# FM33FH0XX register map
File version: 1.0
CPU: SC000 r1p0, little endian, no MPU, no FPU, 3 interrupt priority bits
Registers are 32-bit, read-write, reset 0x0 unless marked. A register's access mark holds for its fields unless they carry their own. Offsets are from the block's base; [hi:lo] are bit positions.

## BSTIM16 — BSTIM16 module information
Base 0x4001B400
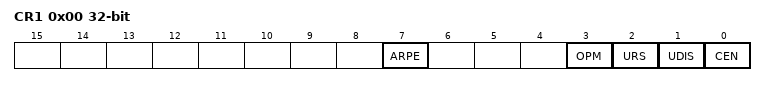
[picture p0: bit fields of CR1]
0x00 CR1
  [7] ARPE — ARPE field description
  [3] OPM — OPM field description
  [2] URS — URS field description
  [1] UDIS — UDIS field description
  [0] CEN — CEN field description
0x04 CR2
  [6:4] MMS — MMS field description
0x0C DIER
  [0] UIE — UIE field description
0x10 ISR
  [0] UIF — UIF field description
0x14 EGR
  [0] UG ro — UG field description
0x24 CNT
  [15:0] CNT ro — CNT field description
0x28 PSC
  [15:0] PSC — PSC field description
0x2C ARR
  [15:0] ARR — ARR field description

## CLM0 — CLM0 module information
Base 0x4001C000
Same registers: CLM1 0x4001C400, CLM2 0x4001C800
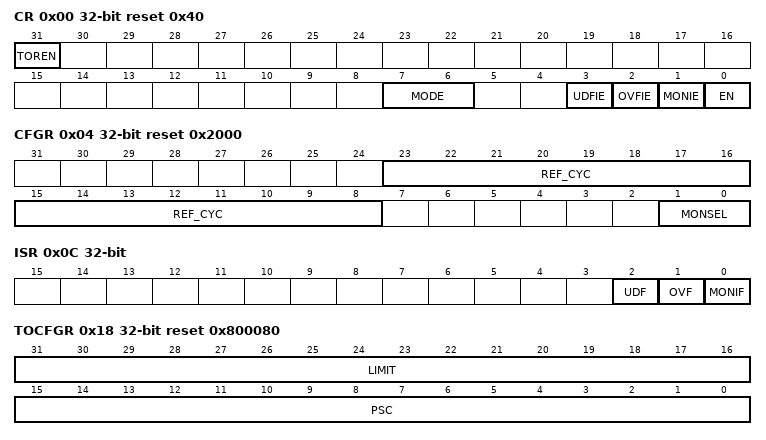
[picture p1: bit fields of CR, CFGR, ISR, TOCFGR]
0x00 CR reset 0x40
  [31] TOREN — TOREN field description
  [7:6] MODE — MODE field description
  [3] UDFIE — UDFIE field description
  [2] OVFIE — OVFIE field description
  [1] MONIE — MONIE field description
  [0] EN — EN field description
0x04 CFGR reset 0x2000
  [23:8] REF_CYC — REF_CYC field description
  [1:0] MONSEL — MONSEL field description
0x08 CNTR
  [23:0] CNT ro — CNT field description
0x0C ISR
  [2] UDF — UDF field description
  [1] OVF — OVF field description
  [0] MONIF — MONIF field description
0x10 CMPH reset 0xFF0000
  [23:0] CMPH — CMPH field description
0x14 CMPL reset 0xFF
  [23:0] CMPL — CMPL field description
0x18 TOCFGR reset 0x800080
  [31:16] LIMIT — LIMIT field description
  [15:0] PSC — PSC field description

## COMP — COMP module information
Base 0x40019C00
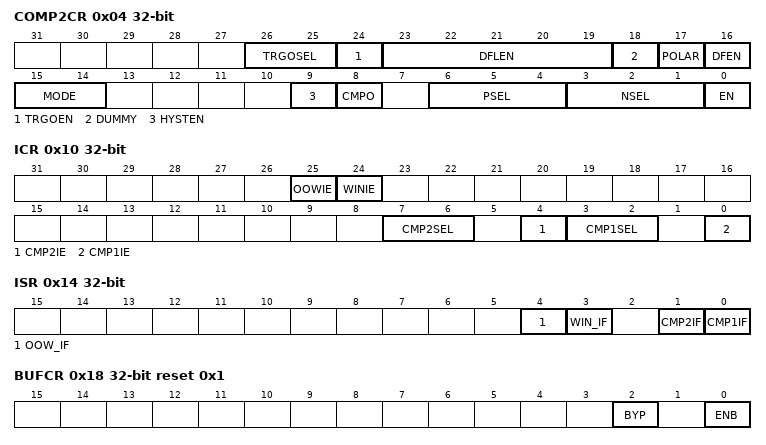
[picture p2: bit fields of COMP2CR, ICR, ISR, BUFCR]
0x04 COMP2CR
  [26:25] TRGOSEL — TRGOSEL field description
  [24] TRGOEN — TRGOEN field description
  [23:19] DFLEN — DFLEN field description
  [18] DUMMY — DUMMY field description
  [17] POLAR — POLAR field description
  [16] DFEN — DFEN field description
  [15:14] MODE — MODE field description
  [9] HYSTEN — HYSTEN field description
  [8] CMPO ro — CMPO field description
  [6:4] PSEL — PSEL field description
  [3:1] NSEL — NSEL field description
  [0] EN — EN field description
0x10 ICR
  [25] OOWIE — OOWIE field description
  [24] WINIE — WINIE field description
  [7:6] CMP2SEL — CMP2SEL field description
  [4] CMP2IE — CMP2IE field description
  [3:2] CMP1SEL — CMP1SEL field description
  [0] CMP1IE — CMP1IE field description
0x14 ISR
  [4] OOW_IF — OOW_IF field description
  [3] WIN_IF — WIN_IF field description
  [1] CMP2IF — CMP2IF field description
  [0] CMP1IF — CMP1IF field description
0x18 BUFCR reset 0x1
  [2] BYP — BYP field description
  [0] ENB — ENB field description

## CRC — CRC module information
Base 0x40018000
0x00 DR reset 0xFFFFFFFF
  [31:0] DR — DR field description
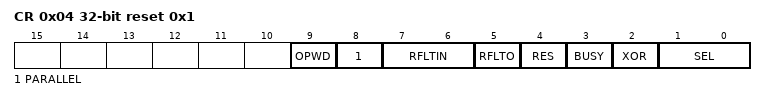
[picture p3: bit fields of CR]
0x04 CR reset 0x1
  [9] OPWD — OPWD field description
  [8] PARALLEL — PARALLEL field description
  [7:6] RFLTIN — RFLTIN field description
  [5] RFLTO — RFLTO field description
  [4] RES ro — RES field description
  [3] BUSY ro — BUSY field description
  [2] XOR — XOR field description
  [1:0] SEL — SEL field description
0x08 LFSR reset 0xFFFFFFFF
  [31:0] LFSR — LFSR field description
0x0C XOR
  [31:0] XOR — XOR field description
0x1C POLY reset 0x1021
  [31:0] POLY — POLY field description

## DAC — DAC module information
Base 0x40012C00
0x00 CR1
  [0] EN — EN field description
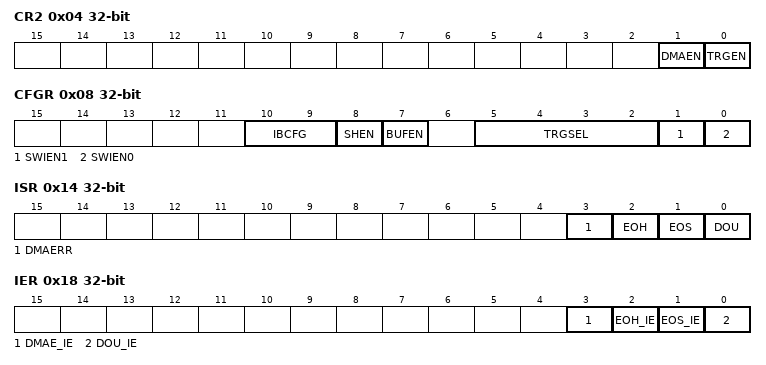
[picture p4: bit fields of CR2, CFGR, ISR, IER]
0x04 CR2
  [1] DMAEN — DMAEN field description
  [0] TRGEN — TRGEN field description
0x08 CFGR
  [10:9] IBCFG ro — IBCFG field description
  [8] SHEN — SHEN field description
  [7] BUFEN — BUFEN field description
  [5:2] TRGSEL — TRGSEL field description
  [1] SWIEN1 — SWIEN1 field description
  [0] SWIEN0 — SWIEN0 field description
0x0C SWTRGR
  [0] SWTRIG wo — SWTRIG field description
0x10 DHR
  [9:0] DHR — DHR field description
0x14 ISR
  [3] DMAERR — DMAERR field description
  [2] EOH — EOH field description
  [1] EOS — EOS field description
  [0] DOU — DOU field description
0x18 IER
  [3] DMAE_IE — DMAE_IE field description
  [2] EOH_IE — EOH_IE field description
  [1] EOS_IE — EOS_IE field description
  [0] DOU_IE — DOU_IE field description
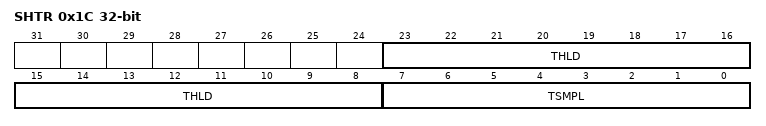
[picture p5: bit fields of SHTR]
0x1C SHTR
  [23:8] THLD — THLD field description
  [7:0] TSMPL — TSMPL field description
